VERSION "BMS_demo v0.7"

NS_ :

BS_:

BU_: S32K344_BMS PCAN

BO_ 512 BMS_DebugCommand: 1 PCAN
 SG_ DebugCommand : 0|8@1+ (1,0) [0|255] "" S32K344_BMS

BO_ 513 BMS_ControlCommand: 1 PCAN
 SG_ ControlCommand : 0|8@1+ (1,0) [0|3] "" S32K344_BMS

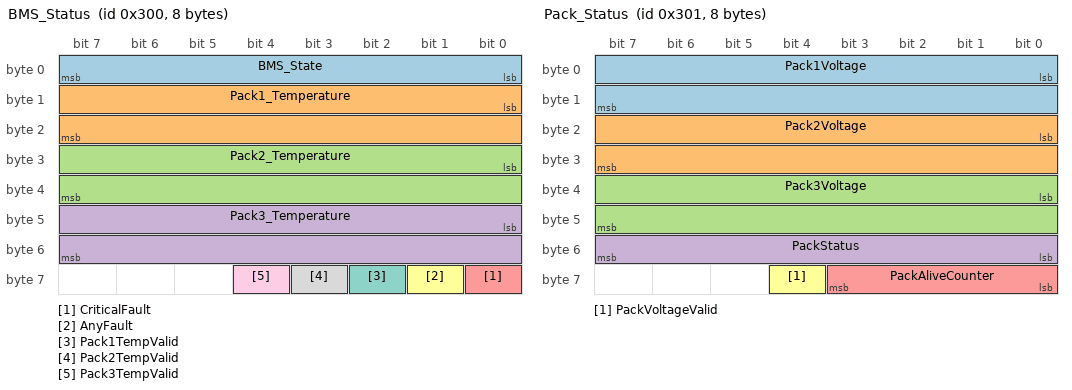
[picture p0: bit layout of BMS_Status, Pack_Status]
BO_ 768 BMS_Status: 8 S32K344_BMS
 SG_ BMS_State : 0|8@1+ (1,0) [0|3] "" PCAN
 SG_ Pack1_Temperature : 8|16@1- (0.1,0) [-100|200] "degC" PCAN
 SG_ Pack2_Temperature : 24|16@1- (0.1,0) [-100|200] "degC" PCAN
 SG_ Pack3_Temperature : 40|16@1- (0.1,0) [-100|200] "degC" PCAN
 SG_ CriticalFault : 56|1@1+ (1,0) [0|1] "" PCAN
 SG_ AnyFault : 57|1@1+ (1,0) [0|1] "" PCAN
 SG_ Pack1TempValid : 58|1@1+ (1,0) [0|1] "" PCAN
 SG_ Pack2TempValid : 59|1@1+ (1,0) [0|1] "" PCAN
 SG_ Pack3TempValid : 60|1@1+ (1,0) [0|1] "" PCAN

BO_ 769 Pack_Status: 8 S32K344_BMS
 SG_ Pack1Voltage : 0|16@1+ (0.1,0) [0|6553.5] "V" PCAN
 SG_ Pack2Voltage : 16|16@1+ (0.1,0) [0|6553.5] "V" PCAN
 SG_ Pack3Voltage : 32|16@1+ (0.1,0) [0|6553.5] "V" PCAN
 SG_ PackStatus : 48|8@1+ (1,0) [0|255] "" PCAN
 SG_ PackAliveCounter : 56|4@1+ (1,0) [0|15] "" PCAN
 SG_ PackVoltageValid : 60|1@1+ (1,0) [0|1] "" PCAN

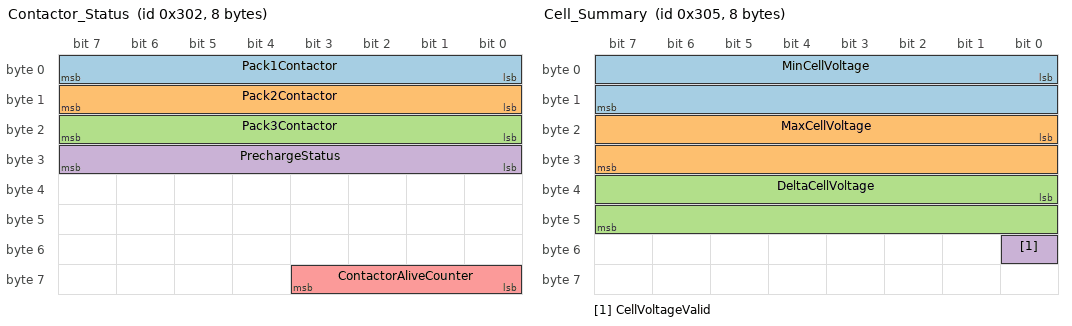
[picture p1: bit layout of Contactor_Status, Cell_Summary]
BO_ 770 Contactor_Status: 8 S32K344_BMS
 SG_ Pack1Contactor : 0|8@1+ (1,0) [0|255] "" PCAN
 SG_ Pack2Contactor : 8|8@1+ (1,0) [0|255] "" PCAN
 SG_ Pack3Contactor : 16|8@1+ (1,0) [0|255] "" PCAN
 SG_ PrechargeStatus : 24|8@1+ (1,0) [0|255] "" PCAN
 SG_ ContactorAliveCounter : 56|4@1+ (1,0) [0|15] "" PCAN

BO_ 771 Pack12_Fault: 8 S32K344_BMS
 SG_ Pack1FaultMask : 0|32@1+ (1,0) [0|4294967295] "" PCAN
 SG_ Pack2FaultMask : 32|32@1+ (1,0) [0|4294967295] "" PCAN

BO_ 772 Pack3_System_Fault: 8 S32K344_BMS
 SG_ Pack3FaultMask : 0|32@1+ (1,0) [0|4294967295] "" PCAN
 SG_ SystemFaultMask : 32|32@1+ (1,0) [0|4294967295] "" PCAN

BO_ 773 Cell_Summary: 8 S32K344_BMS
 SG_ MinCellVoltage : 0|16@1+ (0.001,0) [0|65.535] "V" PCAN
 SG_ MaxCellVoltage : 16|16@1+ (0.001,0) [0|65.535] "V" PCAN
 SG_ DeltaCellVoltage : 32|16@1+ (0.001,0) [0|65.535] "V" PCAN
 SG_ CellVoltageValid : 48|1@1+ (1,0) [0|1] "" PCAN

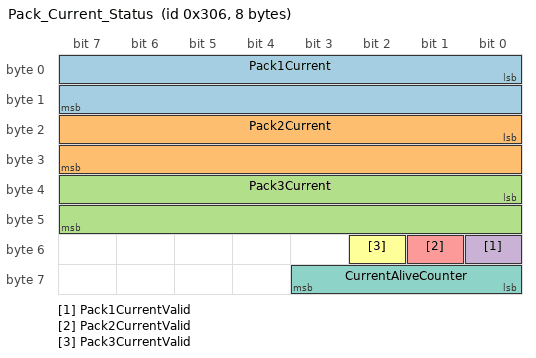
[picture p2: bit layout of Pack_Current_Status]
BO_ 774 Pack_Current_Status: 8 S32K344_BMS
 SG_ Pack1Current : 0|16@1- (0.1,0) [-3276.8|3276.7] "A" PCAN
 SG_ Pack2Current : 16|16@1- (0.1,0) [-3276.8|3276.7] "A" PCAN
 SG_ Pack3Current : 32|16@1- (0.1,0) [-3276.8|3276.7] "A" PCAN
 SG_ Pack1CurrentValid : 48|1@1+ (1,0) [0|1] "" PCAN
 SG_ Pack2CurrentValid : 49|1@1+ (1,0) [0|1] "" PCAN
 SG_ Pack3CurrentValid : 50|1@1+ (1,0) [0|1] "" PCAN
 SG_ CurrentAliveCounter : 56|4@1+ (1,0) [0|15] "" PCAN

    0 "NOP"
    1 "LED2_On"
    2 "LED2_Off"
    3 "Reset_Rx_Count";

    0 "NOP"
    1 "Enable"
    2 "Disable"
    3 "ClearFault";

    0 "INIT"
    1 "STANDBY"
    2 "ACTIVE"
    3 "FAULT";

    0 "No"
    1 "Yes";

    0 "No"
    1 "Yes";

    0 "Invalid"
    1 "Valid";

    0 "Invalid"
    1 "Valid";

    0 "Invalid"
    1 "Valid";

    0 "Invalid"
    1 "Valid";

    0 "Invalid"
    1 "Valid";

    0 "Invalid"
    1 "Valid";

    0 "Invalid"
    1 "Valid";

    0 "Invalid"
    1 "Valid";

CM_ BO_ 512
    "Debug command frame. CAN ID 0x200.";

CM_ BO_ 513
    "BMS control command frame. CAN ID 0x201. Byte0: 0=NOP, 1=Enable, 2=Disable, 3=ClearFault.";

CM_ BO_ 768
    "BMS status frame. CAN ID 0x300. Nominal transmit period 100 ms.";

CM_ SG_ 768 Pack1_Temperature
    "Pack 1 NTC temperature. Signed 16-bit little-endian. 0.1 degC/bit.";

CM_ SG_ 768 Pack2_Temperature
    "Pack 2 NTC temperature. Signed 16-bit little-endian. 0.1 degC/bit.";

CM_ SG_ 768 Pack3_Temperature
    "Pack 3 NTC temperature. Signed 16-bit little-endian. 0.1 degC/bit.";

CM_ BO_ 769
    "Pack voltage/status frame. CAN ID 0x301.";

CM_ BO_ 770
    "Contactor status frame. CAN ID 0x302.";

CM_ BO_ 771
    "Pack 1 and Pack 2 fault mask frame. CAN ID 0x303.";

CM_ BO_ 772
    "Pack 3 and system fault mask frame. CAN ID 0x304.";

CM_ BO_ 773
    "Cell voltage summary frame. CAN ID 0x305.";

CM_ BO_ 774
    "Pack current status frame. CAN ID 0x306. Nominal transmit period 100 ms.";

CM_ SG_ 774 Pack1Current
    "Pack 1 current. Positive = discharge, negative = charge. Signed 16-bit little-endian, 0.1 A/bit.";

CM_ SG_ 774 Pack2Current
    "Pack 2 current. Positive = discharge, negative = charge. Signed 16-bit little-endian, 0.1 A/bit.";

CM_ SG_ 774 Pack3Current
    "Pack 3 current. Positive = discharge, negative = charge. Signed 16-bit little-endian, 0.1 A/bit.";

CM_ SG_ 774 CurrentAliveCounter
    "4-bit alive counter incremented after a successful 0x306 transmission.";
